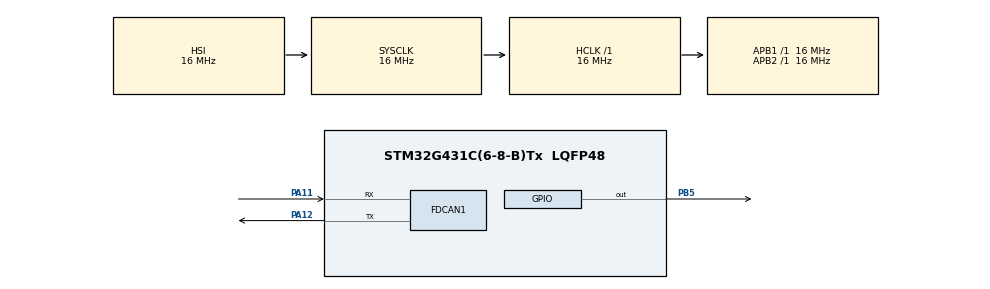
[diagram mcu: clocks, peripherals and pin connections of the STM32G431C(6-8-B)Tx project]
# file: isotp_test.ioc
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FDCAN1.AutoRetransmission=ENABLE
FDCAN1.CalculateBaudRateNominal=500000
FDCAN1.CalculateTimeBitNominal=2000
FDCAN1.CalculateTimeQuantumNominal=62.5
FDCAN1.DataSyncJumpWidth=15
FDCAN1.DataTimeSeg1=16
FDCAN1.DataTimeSeg2=15
FDCAN1.NominalPrescaler=1
FDCAN1.NominalSyncJumpWidth=2
FDCAN1.NominalTimeSeg1=29
FDCAN1.NominalTimeSeg2=2
FDCAN1.StdFiltersNbr=1
Mcu.Family=STM32G4
Mcu.Name=STM32G431C(6-8-B)Tx
Mcu.Package=LQFP48
NVIC.FDCAN1_IT0_IRQn=true\:0\:0\:false\:false\:true\:true\:true\:true
NVIC.PriorityGroup=NVIC_PRIORITYGROUP_4
PA11.Mode=FDCAN_Activate
PA11.Signal=FDCAN1_RX
PA12.Mode=FDCAN_Activate
PA12.Signal=FDCAN1_TX
PB5.Signal=GPIO_Output
ProjectManager.HeapSize=0x200
ProjectManager.StackSize=0x400
ProjectManager.TargetToolchain=CMake
RCC.AHBFreq_Value=16000000
RCC.APB1Freq_Value=16000000
RCC.APB1TimFreq_Value=16000000
RCC.APB2Freq_Value=16000000
RCC.APB2TimFreq_Value=16000000
RCC.CortexFreq_Value=16000000
RCC.EXTERNAL_CLOCK_VALUE=12288000
RCC.HCLKFreq_Value=16000000
RCC.HSE_VALUE=8000000
RCC.HSI48_VALUE=48000000
RCC.HSI_VALUE=16000000
RCC.LSE_VALUE=32768
RCC.PLLN=12
RCC.PLLQ=RCC_PLLQ_DIV4
RCC.SYSCLKFreq_VALUE=16000000
RCC.USBFreq_Value=48000000
RCC.VCOOutputFreq_Value=192000000
RNG.ClockErrorDetection=RNG_CED_ENABLE
VP_RNG_VS_RNG.Mode=RNG_Activate
VP_SYS_VS_DBSignals.Mode=DisableDeadBatterySignals
board=custom

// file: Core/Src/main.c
/* USER CODE BEGIN Header */
/**
  ******************************************************************************
  * @file           : main.c
  * @brief          : Main program body
  ******************************************************************************
  * @attention
  *
  * Copyright (c) 2026 STMicroelectronics.
  * All rights reserved.
  *
  * This software is licensed under terms that can be found in the LICENSE file
  * in the root directory of this software component.
  * If no LICENSE file comes with this software, it is provided AS-IS.
  *
  ******************************************************************************
  */
/* USER CODE END Header */
#include "main.h"
#include "fdcan.h"
#include "rng.h"
#include "gpio.h"

/* USER CODE BEGIN Includes */
#include "uds/uds.h"
#include "drivers/flash_driver.h"
#include "sr_errno.h"
/* USER CODE END Includes */

void SystemClock_Config(void);

int main(void)
{

  /* MCU Configuration--------------------------------------------------------*/

  /* Reset of all peripherals, Initializes the Flash interface and the Systick. */
  HAL_Init();

  /* Configure the system clock */
  SystemClock_Config();

  /* Initialize all configured peripherals */
  MX_GPIO_Init();
  MX_FDCAN1_Init();
  MX_RNG_Init();
  /* USER CODE BEGIN 2 */

  // ================= bring up the can -> isotp -> uds stack and serve
  // only returns if the stack fails to start
  if (sr_uds_server_start(&hfdcan1) != SR_OK) {
      for(int i = 0; i < 5; i++) {
          HAL_GPIO_TogglePin(GPIOB, GPIO_PIN_5);
          HAL_Delay(1000);
          HAL_GPIO_TogglePin(GPIOB, GPIO_PIN_5);
          HAL_Delay(1000);
      }
      return 1;
  }
  /* USER CODE END 2 */

  /* Infinite loop */
  while (1)
  {

  }
}

void SystemClock_Config(void)
{
  RCC_OscInitTypeDef RCC_OscInitStruct = {0};
  RCC_ClkInitTypeDef RCC_ClkInitStruct = {0};

  /** Configure the main internal regulator output voltage
  */
  HAL_PWREx_ControlVoltageScaling(PWR_REGULATOR_VOLTAGE_SCALE1);

  /** Initializes the RCC Oscillators according to the specified parameters
  * in the RCC_OscInitTypeDef structure.
  */
  RCC_OscInitStruct.OscillatorType = RCC_OSCILLATORTYPE_HSI;
  RCC_OscInitStruct.HSIState = RCC_HSI_ON;
  RCC_OscInitStruct.HSICalibrationValue = RCC_HSICALIBRATION_DEFAULT;
  RCC_OscInitStruct.PLL.PLLState = RCC_PLL_ON;
  RCC_OscInitStruct.PLL.PLLSource = RCC_PLLSOURCE_HSI;
  RCC_OscInitStruct.PLL.PLLM = RCC_PLLM_DIV1;
  RCC_OscInitStruct.PLL.PLLN = 12;
  RCC_OscInitStruct.PLL.PLLP = RCC_PLLP_DIV2;
  RCC_OscInitStruct.PLL.PLLQ = RCC_PLLQ_DIV4;
  RCC_OscInitStruct.PLL.PLLR = RCC_PLLR_DIV2;
  if (HAL_RCC_OscConfig(&RCC_OscInitStruct) != HAL_OK)
  {
    Error_Handler();
  }

  /** Initializes the CPU, AHB and APB buses clocks
  */
  RCC_ClkInitStruct.ClockType = RCC_CLOCKTYPE_HCLK|RCC_CLOCKTYPE_SYSCLK
                              |RCC_CLOCKTYPE_PCLK1|RCC_CLOCKTYPE_PCLK2;
  RCC_ClkInitStruct.SYSCLKSource = RCC_SYSCLKSOURCE_HSI;
  RCC_ClkInitStruct.AHBCLKDivider = RCC_SYSCLK_DIV1;
  RCC_ClkInitStruct.APB1CLKDivider = RCC_HCLK_DIV1;
  RCC_ClkInitStruct.APB2CLKDivider = RCC_HCLK_DIV1;

  if (HAL_RCC_ClockConfig(&RCC_ClkInitStruct, FLASH_LATENCY_0) != HAL_OK)
  {
    Error_Handler();
  }
}

void Error_Handler(void)
{
  __disable_irq();
  while (1)
  {
  }
}
